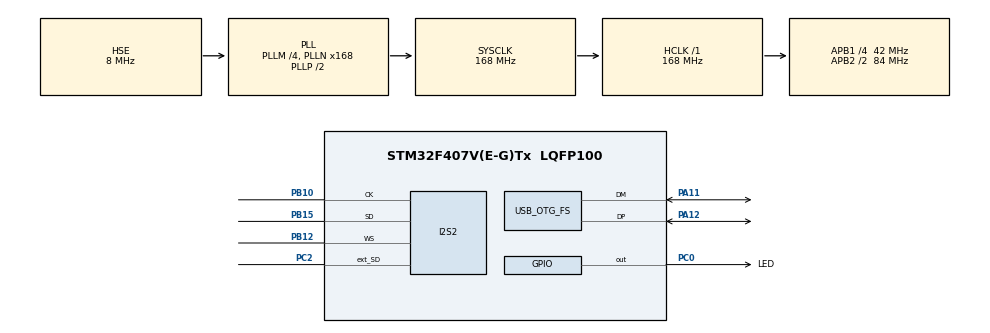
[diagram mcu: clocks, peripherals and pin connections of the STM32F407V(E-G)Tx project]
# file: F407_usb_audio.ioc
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Dma.Request0=SPI2_TX
Dma.SPI2_TX.0.Direction=DMA_MEMORY_TO_PERIPH
Dma.SPI2_TX.0.FIFOMode=DMA_FIFOMODE_ENABLE
Dma.SPI2_TX.0.FIFOThreshold=DMA_FIFO_THRESHOLD_FULL
Dma.SPI2_TX.0.Instance=DMA1_Stream4
Dma.SPI2_TX.0.MemBurst=DMA_MBURST_SINGLE
Dma.SPI2_TX.0.MemDataAlignment=DMA_MDATAALIGN_HALFWORD
Dma.SPI2_TX.0.MemInc=DMA_MINC_ENABLE
Dma.SPI2_TX.0.Mode=DMA_NORMAL
Dma.SPI2_TX.0.PeriphBurst=DMA_PBURST_SINGLE
Dma.SPI2_TX.0.PeriphDataAlignment=DMA_PDATAALIGN_HALFWORD
Dma.SPI2_TX.0.PeriphInc=DMA_PINC_DISABLE
Dma.SPI2_TX.0.Priority=DMA_PRIORITY_VERY_HIGH
I2S2.AudioFreq=I2S_AUDIOFREQ_48K
I2S2.DataFormat=I2S_DATAFORMAT_16B_EXTENDED
I2S2.ErrorAudioFreq=1.72 %
I2S2.FullDuplexMode=I2S_FULLDUPLEXMODE_ENABLE
I2S2.Instance=SPI$Index
I2S2.RealAudioFreq=48.828 KHz
I2S2.VirtualMode=I2S_MODE_MASTER
Mcu.Family=STM32F4
Mcu.Name=STM32F407V(E-G)Tx
Mcu.Package=LQFP100
NVIC.DMA1_Stream4_IRQn=true\:0\:0\:false\:false\:true\:false\:true\:true
NVIC.OTG_FS_IRQn=true\:0\:0\:false\:false\:true\:true\:true\:true
NVIC.PriorityGroup=NVIC_PRIORITYGROUP_4
PA11.Mode=Device_Only
PA11.Signal=USB_OTG_FS_DM
PA12.Mode=Device_Only
PA12.Signal=USB_OTG_FS_DP
PA13.Mode=Serial_Wire
PA13.Signal=SYS_JTMS-SWDIO
PA14.Mode=Serial_Wire
PA14.Signal=SYS_JTCK-SWCLK
PB10.Mode=Full_Duplex_Master
PB10.Signal=I2S2_CK
PB12.Mode=Full_Duplex_Master
PB12.Signal=I2S2_WS
PB15.Mode=Full_Duplex_Master
PB15.Signal=I2S2_SD
PC0.GPIO_Label=LED
PC0.GPIO_Speed=GPIO_SPEED_FREQ_VERY_HIGH
PC0.Signal=GPIO_Output
PC14-OSC32_IN.Mode=LSE-External-Oscillator
PC14-OSC32_IN.Signal=RCC_OSC32_IN
PC15-OSC32_OUT.Mode=LSE-External-Oscillator
PC15-OSC32_OUT.Signal=RCC_OSC32_OUT
PC2.Mode=Full_Duplex_Master
PC2.Signal=I2S2_ext_SD
PH0-OSC_IN.Mode=HSE-External-Oscillator
PH0-OSC_IN.Signal=RCC_OSC_IN
PH1-OSC_OUT.Mode=HSE-External-Oscillator
PH1-OSC_OUT.Signal=RCC_OSC_OUT
ProjectManager.HeapSize=0x4000
ProjectManager.StackSize=0x2000
ProjectManager.TargetToolchain=STM32CubeIDE
RCC.48MHZClocksFreq_Value=48000000
RCC.AHBFreq_Value=168000000
RCC.APB1CLKDivider=RCC_HCLK_DIV4
RCC.APB1Freq_Value=42000000
RCC.APB1TimFreq_Value=84000000
RCC.APB2CLKDivider=RCC_HCLK_DIV2
RCC.APB2Freq_Value=84000000
RCC.APB2TimFreq_Value=168000000
RCC.CortexFreq_Value=168000000
RCC.EnbaleCSS=true
RCC.HCLKFreq_Value=168000000
RCC.HSE_VALUE=8000000
RCC.HSI_VALUE=16000000
RCC.LockedElements=USBOTGOutput,I2SClocksOutput
RCC.PLLI2SN=50
RCC.PLLM=4
RCC.PLLN=168
RCC.PLLQ=7
RCC.SYSCLKFreq_VALUE=168000000
RCC.SYSCLKSource=RCC_SYSCLKSOURCE_PLLCLK
RCC.VCOOutputFreq_Value=336000000
USB_DEVICE.CLASS_NAME_FS=AUDIO
USB_DEVICE.PRODUCT_STRING_AUDIO_FS=Neuronix PCM5102/PCM1808
USB_DEVICE.USBD_AUDIO_FREQ-AUDIO_FS=48000
USB_DEVICE.USBD_MAX_NUM_INTERFACES-AUDIO_FS=2
USB_DEVICE.VirtualMode-AUDIO_FS=Audio
USB_DEVICE.VirtualModeFS=Audio_FS
USB_OTG_FS.VirtualMode=Device_Only
VP_USB_DEVICE_VS_USB_DEVICE_AUDIO_FS.Mode=AUDIO_FS
board=custom

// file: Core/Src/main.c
/* USER CODE BEGIN Header */
/**
  ******************************************************************************
  * @file           : main.c
  * @brief          : Main program body
  ******************************************************************************
  * @attention
  *
  * Copyright (c) 2022 STMicroelectronics.
  * All rights reserved.
  *
  * This software is licensed under terms that can be found in the LICENSE file
  * in the root directory of this software component.
  * If no LICENSE file comes with this software, it is provided AS-IS.
  *
  ******************************************************************************
  */
/*| 3.3V | 3.3V on Nucleo board  |
| FLT  | Filter select, grounded: select normal latency, grounded  |
| DMP  | De-emphasis control, grounded(OFF)  |
| SCL  | System clock input, in datasheet SCK pin. System clock is internally generated, it should not be wired anywhere  |
| BCK  | Audio data bit clock input. In I2S terminology is equivalent to serial clock(SCK) I've connected it to `PB10 > I2S2_CK` |
| DIN  | Audio data input. This is Serial Data pin, I've connected it to `PC3 > I2S2_SD` |
| LCK  | Is LRCK in PCM5102 datasheet, which is Audio data word clock input. It is used to switch data for left and right channel. In I2S is I2SX_WS pin, means "Word Select" pin. Connect it to `PB12 > I2S2_WS` |
| FMT  | Audio Format Selection, we select I2S, so this should be grounded  |
| XMT  | In dataseet is XSMT, which is mute control, should be HIGH to unmute.  |
*/
/* USER CODE END Header */
#include "main.h"
#include "dma.h"
#include "i2s.h"
#include "usb_device.h"
#include "gpio.h"

/* USER CODE BEGIN Includes */
#include "audio_fw_glo.h"
#include "greq_glo.h"
/* USER CODE END Includes */

/* USER CODE BEGIN PV */
__IO int16_t                 UpdatePointer = 0;
/* USER CODE END PV */

void SystemClock_Config(void);

int main(void)
{

  /* MCU Configuration--------------------------------------------------------*/

  /* Reset of all peripherals, Initializes the Flash interface and the Systick. */
  HAL_Init();

  /* Configure the system clock */
  SystemClock_Config();

  /* Initialize all configured peripherals */
  MX_GPIO_Init();
  MX_USB_DEVICE_Init();
  MX_DMA_Init();
  MX_I2S2_Init();
  /* USER CODE BEGIN 2 */
  HAL_GPIO_TogglePin(LED_GPIO_Port, LED_Pin);

  /* USER CODE END 2 */

  /* Infinite loop */
  while (1)
  {

  }
}

void SystemClock_Config(void)
{
  RCC_OscInitTypeDef RCC_OscInitStruct = {0};
  RCC_ClkInitTypeDef RCC_ClkInitStruct = {0};

  /** Configure the main internal regulator output voltage
  */
  __HAL_RCC_PWR_CLK_ENABLE();
  __HAL_PWR_VOLTAGESCALING_CONFIG(PWR_REGULATOR_VOLTAGE_SCALE1);

  /** Initializes the RCC Oscillators according to the specified parameters
  * in the RCC_OscInitTypeDef structure.
  */
  RCC_OscInitStruct.OscillatorType = RCC_OSCILLATORTYPE_HSE;
  RCC_OscInitStruct.HSEState = RCC_HSE_ON;
  RCC_OscInitStruct.PLL.PLLState = RCC_PLL_ON;
  RCC_OscInitStruct.PLL.PLLSource = RCC_PLLSOURCE_HSE;
  RCC_OscInitStruct.PLL.PLLM = 4;
  RCC_OscInitStruct.PLL.PLLN = 168;
  RCC_OscInitStruct.PLL.PLLP = RCC_PLLP_DIV2;
  RCC_OscInitStruct.PLL.PLLQ = 7;
  if (HAL_RCC_OscConfig(&RCC_OscInitStruct) != HAL_OK)
  {
    Error_Handler();
  }

  /** Initializes the CPU, AHB and APB buses clocks
  */
  RCC_ClkInitStruct.ClockType = RCC_CLOCKTYPE_HCLK|RCC_CLOCKTYPE_SYSCLK
                              |RCC_CLOCKTYPE_PCLK1|RCC_CLOCKTYPE_PCLK2;
  RCC_ClkInitStruct.SYSCLKSource = RCC_SYSCLKSOURCE_PLLCLK;
  RCC_ClkInitStruct.AHBCLKDivider = RCC_SYSCLK_DIV1;
  RCC_ClkInitStruct.APB1CLKDivider = RCC_HCLK_DIV4;
  RCC_ClkInitStruct.APB2CLKDivider = RCC_HCLK_DIV2;

  if (HAL_RCC_ClockConfig(&RCC_ClkInitStruct, FLASH_LATENCY_5) != HAL_OK)
  {
    Error_Handler();
  }

  /** Enables the Clock Security System
  */
  HAL_RCC_EnableCSS();
}

void Error_Handler(void)
{
  __disable_irq();
  while (1)
  {
  }
}
